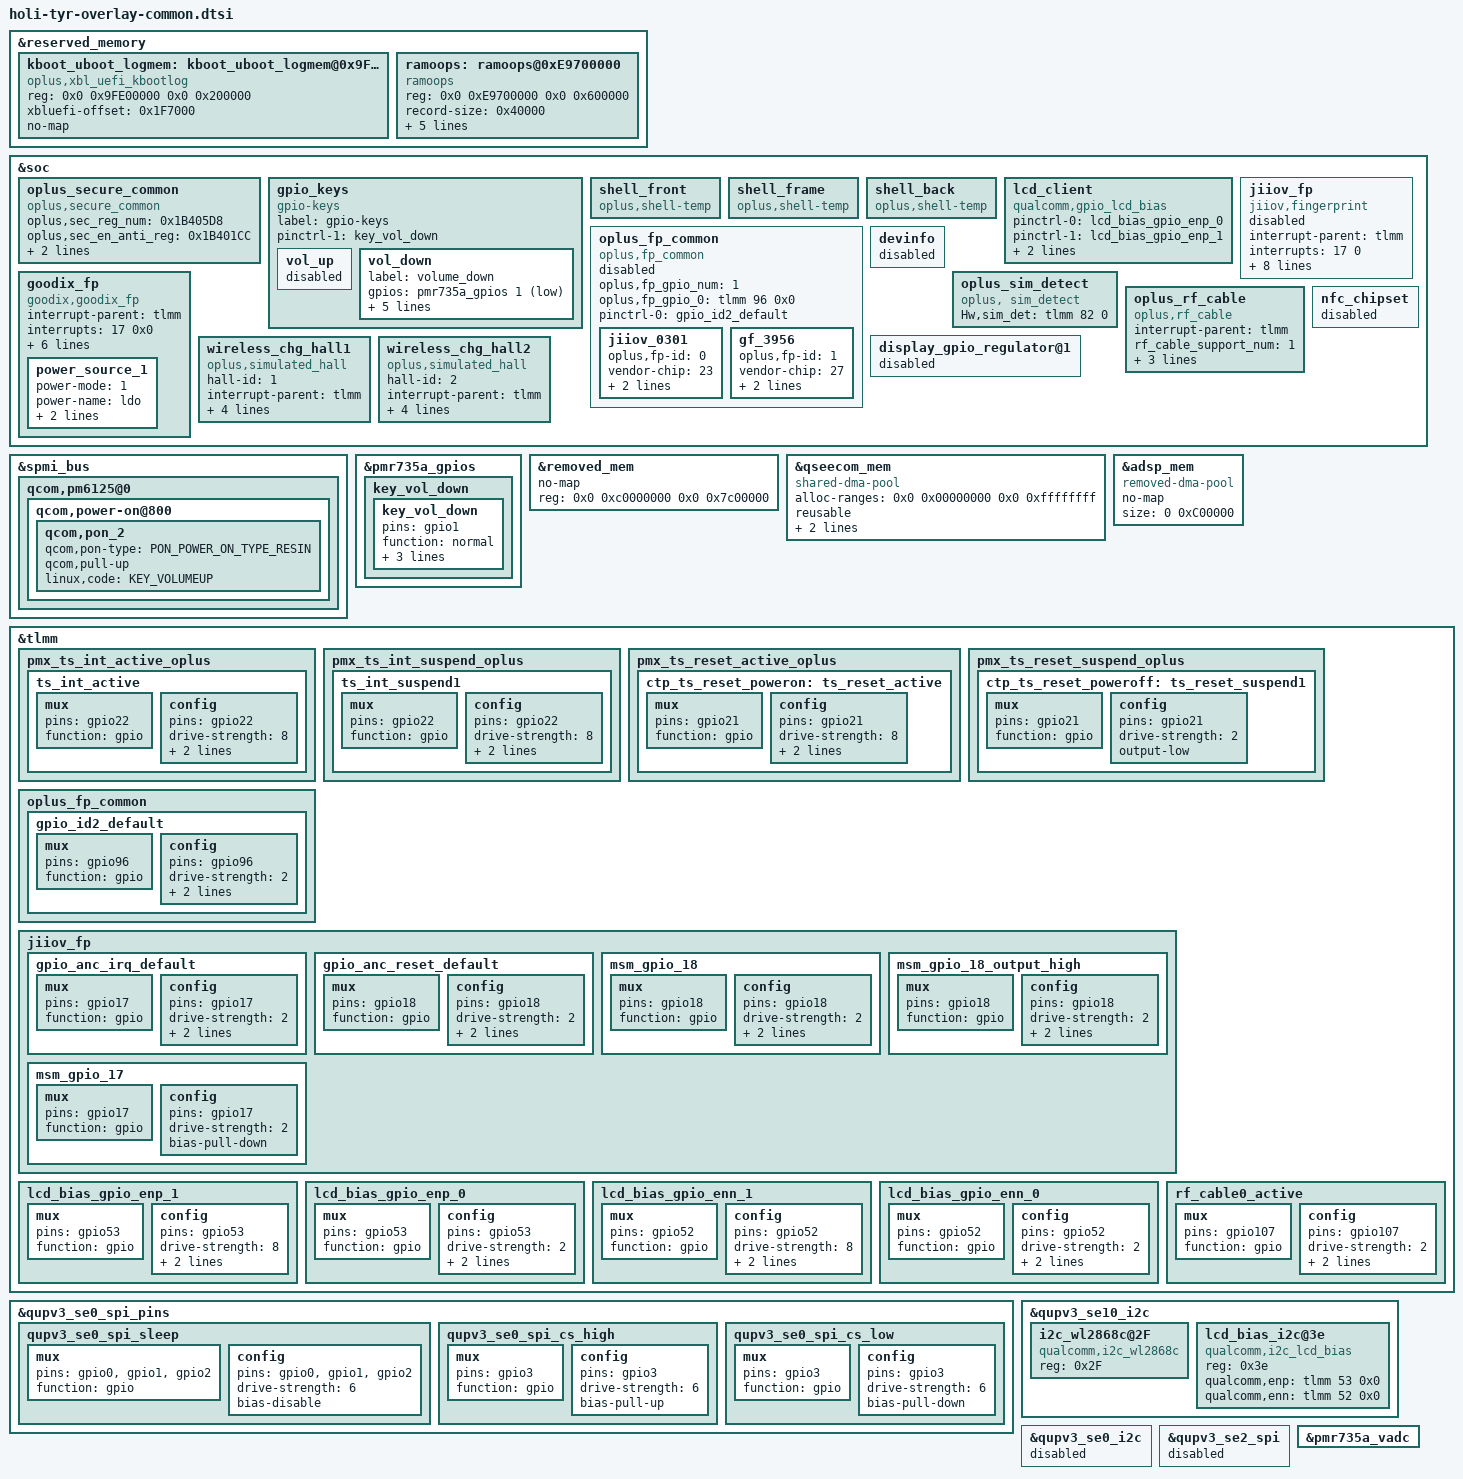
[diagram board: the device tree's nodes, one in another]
#include "../qcom/blair-qrd-nopmi.dtsi"

/* #ifdef OPLUS_ARCH_EXTENDS */
#include "holi-tyr-audio-overlay.dtsi"
/* #endif OPLUS_ARCH_EXTENDS */
/* DTBO: Platform common generic overlay */

&reserved_memory {
	//xbl_uefi_mem address get from: PcdEmbeddedFdBaseAddress +
	//SERIAL_BUFFER_OFFSET = 0x9FC00000 + 0x3F7000 = 0x9FFF7000
	//kernel boot log: 0x9FE00000~ 0x9FFF6FFF, xbl-uefi log: 0x9FFF7000 ~ 0x9FFFFFFF
	kboot_uboot_logmem: kboot_uboot_logmem@0x9FE00000 {
		reg = <0x0 0x9FE00000 0x0 0x200000>;
		compatible = "oplus,xbl_uefi_kbootlog";
		xbluefi-offset = <0x1F7000>;
		no-map;
	};

	//#if IS_ENABLED(CONFIG_OPLUS_FEATURE_DUMP_DEVICE_INFO)
	ramoops: ramoops@0xE9700000 {
		compatible = "ramoops";
		reg = <0x0 0xE9700000 0x0 0x600000>;  //6M
		record-size  = <0x40000>; //256k
		console-size = <0x40000>; //256k
		ftrace-size  = <0x100000>; //1M
		pmsg-size    = <0x100000>; //1M
		devinfo-size = <0x8000>;  //32k
		ecc-size     = <0x0>;
	 };
};

&soc{
	oplus_secure_common {
		compatible = "oplus,secure_common";
		oplus,sec_reg_num = <0x1B405D8>;
		oplus,sec_en_anti_reg = <0x1B401CC>;
		oplus,sec_override1_reg = <0x7860C0>;
		oplus,override1_en_value = <0x1>;
	};
};

&soc {
/*#ifdef OPLUS_FEATURE_TP_BASIC*/
	gpio_keys {
		compatible = "gpio-keys";
		label = "gpio-keys";

		pinctrl-names = "default";
		pinctrl-1 = <&key_vol_down>;
		/* using volume down config update the default value */

		vol_up {
                status="disabled";
		};

		vol_down {
			label = "volume_down";
			gpios = <&pmr735a_gpios 1 GPIO_ACTIVE_LOW>;
			linux,input-type = <1>;
			linux,code = <KEY_VOLUMEDOWN>;
			gpio-key,wakeup;
			debounce-interval = <15>;
			linux,can-disable;
		};
	};

	shell_front {
		compatible = "oplus,shell-temp";
	};

	shell_frame {
		compatible = "oplus,shell-temp";
	};

	shell_back {
		compatible = "oplus,shell-temp";
	};

	//#ifdef OPLUS_BUG_STABILITY
	lcd_client {
		compatible = "qualcomm,gpio_lcd_bias";
		pinctrl-names = "lcd_bias_gpio_enp0","lcd_bias_gpio_enp1","lcd_bias_gpio_enn0","lcd_bias_gpio_enn1";
		pinctrl-0 = <&lcd_bias_gpio_enp_0>;
		pinctrl-1 = <&lcd_bias_gpio_enp_1>;
		pinctrl-2 = <&lcd_bias_gpio_enn_0>;
		pinctrl-3 = <&lcd_bias_gpio_enn_1>;
		status = "okay";
	};
	//#endif
};

&spmi_bus {
	qcom,pm6125@0 {
		qcom,power-on@800 {
/*#ifdef OPLUS_FEATURE_TP_BASIC*/
			qcom,pon_2 {
					qcom,pon-type = <PON_POWER_ON_TYPE_RESIN>;
					qcom,pull-up;
					linux,code = <KEY_VOLUMEUP>;
			};
/*#endif OPLUS_FEATURE_TP_BASIC*/
		};
	};
};

&pmr735a_gpios {
	key_vol_down {
		key_vol_down: key_vol_down {
			pins = "gpio1";
			function = "normal";
			input-enable;
			bias-pull-up;
			power-source = <1>;
		};
	};
};

/* #ifdef OPLUS_FEATURE_CAMERA_COMMON */
//#include "camera/blair-camera-sensor-mtp.dtsi"
/* #endif OPLUS_FEATURE_CAMERA_COMMON */

//#ifdef OPLUS_FEATURE_FINGERPRINT
&soc{
	oplus_fp_common {
		compatible = "oplus,fp_common";
		oplus,fp_gpio_num = <1>;
		oplus,fp_gpio_0 = <&tlmm 96 0x0>;
		pinctrl-names = "default";
		pinctrl-0 = <&gpio_id2_default>;
		status = "disabled";
		jiiov_0301 {
			oplus,fp-id = <0>; /* fp id mapping table */
			vendor-chip = <23>; /* please refer to the struct fp_vendor_t in oplus_fp_commmon.h */
			eng-menu = "-1,-1"; /* represents SNR, inclination test item in engineer menu, and 0/1 means off/on */
			chip-name = "JIIOV_0301";  /* /proc/fp_id, will be displayed in engineer menu  */
		};
	gf_3956 {
            oplus,fp-id = <1>; /* fp id mapping table */
            vendor-chip = <27>; /* please refer to the struct fp_vendor_t in oplus_fp_commmon.n */
            eng-menu = "-1,-1"; /* represents SNR, inclination test item in engineer menu, and 0/1 means off/on */
            chip-name = "G_3956";  /* /proc/fp_id, will be displayed in engineer menu  */
    	};

	};

	jiiov_fp {
		status = "disabled";
		compatible = "jiiov,fingerprint";
		interrupt-parent = <&tlmm>;
		interrupts = <17 0>;
		ldo-supply = <&pm6125_l21>;
		anc,gpio_irq = <&tlmm 17 0x1>;
		anc,gpio_rst = <&tlmm 18 0x0>;
		pinctrl-names = "default", "anc_reset_reset", "anc_reset_active", "anc_irq_active";
		pinctrl-0 = <&gpio_anc_irq_default>, <&gpio_anc_reset_default>;
		pinctrl-1 = <&msm_gpio_18>;
		pinctrl-2 = <&msm_gpio_18_output_high>;
		pinctrl-3 = <&msm_gpio_17>;
	};

	goodix_fp {
		status = "okay";
		compatible = "goodix,goodix_fp";
		interrupt-parent = <&tlmm>;
		interrupts = <17 0x0>;
		//ldo-supply = <&L21A>;
		//power-mode = <1>;
		ldo-supply = <&pm6125_l21>;
		goodix,gpio_irq = <&tlmm 17 0x00>;
		goodix,gpio_reset = <&tlmm 18 0x00>;
		//gpio-power = <&tlmm 47 0x0>;
		notify_tpinfo_flag = <1>;
		ftm_poweroff_flag = <1>;
		ldo-config = <3300000 3300000 150000>;
		power_source_1 {
			power-mode = <1>;
			power-name = "ldo";
			power-config = "ldo-config";
			delay-time = <0>;
		};
		
	};
};
&removed_mem {
	no-map;
	//reg = <0x0 0xc0000000 0x0 0x5100000>;
	reg = <0x0 0xc0000000 0x0 0x7c00000>;
};

&qseecom_mem {
	compatible = "shared-dma-pool";
	alloc-ranges = <0x0 0x00000000 0x0 0xffffffff>;
	reusable;
	alignment = <0x0 0x400000>;
	//size = <0x0 0x1400000>;
	size = <0x0 0x5c00000>;
};
//#endif /*OPLUS_FEATURE_FINGERPRINT*

&adsp_mem {
    compatible = "removed-dma-pool";
    no-map;
    /delete-property/ reusable;
    size = <0 0xC00000>;
};

//#ifdef OPLUS_FEATURE_TP_BASIC
&soc {
	devinfo {
		status = "disabled";
	};

    //#ifdef OPLUS_FEATURE_TP_BASIC
	oplus_sim_detect {
		compatible = "oplus, sim_detect";
		Hw,sim_det = <&tlmm 82 0>;
	};
    //#endif /* OPLUS_FEATURE_TP_BASIC */
};

&tlmm {
	/* add pingrp for touchscreen */
	pmx_ts_int_active_oplus {
		ts_int_active: ts_int_active {
			mux {
				pins = "gpio22";
				function = "gpio";
			};

			config {
				pins = "gpio22";
				drive-strength = <8>;
				bias-disable;
				input-enable;
			};
		};
	};

	pmx_ts_int_suspend_oplus {
		ts_int_suspend1: ts_int_suspend1 {
			mux {
				pins = "gpio22";
				function = "gpio";
			};

			config {
				pins = "gpio22";
				drive-strength = <8>;
				//bias-pull-down;
				bias-pull-up;
				input-enable;
			};
		};
	};

	pmx_ts_reset_active_oplus {
		ctp_ts_reset_poweron: ts_reset_active {
			mux {
				pins = "gpio21";
				function = "gpio";
			};

			config {
				pins = "gpio21";
				drive-strength = <8>;
				output-high;
				bias-disable;
			};
		};
	};

	pmx_ts_reset_suspend_oplus {
		ctp_ts_reset_poweroff: ts_reset_suspend1 {
			mux {
				pins = "gpio21";
				function = "gpio";
			};

			config {
				pins = "gpio21";
				drive-strength = <2>;
				output-low;
			};
		};
	};

	//#ifdef OPLUS_FEATURE_FINGERPRINT
	oplus_fp_common{
		gpio_id2_default: gpio_id2_default {
			mux {
				pins = "gpio96";
				function = "gpio";
			};
			config {
				pins = "gpio96";
				drive-strength = <2>;
				bias-pull-up;
				input-enable;
			};
		};
	};

	jiiov_fp{
		gpio_anc_irq_default: gpio_anc_irq_default {
			mux {
				pins = "gpio17";
				function = "gpio";
			};
			config {
				pins = "gpio17";
				drive-strength = <2>;
				bias-pull-down;
				input-enable;
			};
		};
		gpio_anc_reset_default: gpio_anc_reset_default {
			mux {
				pins = "gpio18";
				function = "gpio";
			};
			config {
				pins = "gpio18";
				drive-strength = <2>;
				bias-disable;
				output-low;
			};
		};

		msm_gpio_18: msm_gpio_18 {
			mux {
				pins = "gpio18";
				function = "gpio";
			};

			config {
				pins = "gpio18";
				drive-strength = <2>;
				bias-disable;
				output-low;
			};
		};

		msm_gpio_18_output_high: msm_gpio_18_output_high {
			mux {
				pins = "gpio18";
				function = "gpio";
			};

			config {
				pins = "gpio18";
				drive-strength = <2>;
				bias-disable;
				output-high;
			};
		};

		msm_gpio_17: msm_gpio_17 {
			mux {
				pins = "gpio17";
				function = "gpio";
			};

			config {
				pins = "gpio17";
				drive-strength = <2>;
				bias-pull-down;
			};
		};
	};
	//#endif /*OPLUS_FEATURE_FINGERPRINT*


	//#ifdef OPLUS_BUG_STABILITY
	lcd_bias_gpio_enp_1: lcd_bias_gpio_enp_1 {
		mux {
			pins = "gpio53";
			function = "gpio";
		};

		config {
			pins = "gpio53";
			drive-strength = <8>;
			output-high;
			bias-pull-up;
		};
	};

	lcd_bias_gpio_enp_0: lcd_bias_gpio_enp_0 {
		mux {
			pins = "gpio53";
			function = "gpio";
		};

		config {
			pins = "gpio53";
			drive-strength = <2>;
			output-low;
			bias-pull-down;
		};
	};

	lcd_bias_gpio_enn_1: lcd_bias_gpio_enn_1 {
		mux {
			pins = "gpio52";
			function = "gpio";
		};

		config {
			pins = "gpio52";
			drive-strength = <8>;
			output-high;
			bias-pull-up;
		};
	};

	lcd_bias_gpio_enn_0: lcd_bias_gpio_enn_0 {
		mux {
			pins = "gpio52";
			function = "gpio";
		};

		config {
			pins = "gpio52";
			drive-strength = <2>;
			output-low;
			bias-pull-down;
		};
	};
	//#endif
};

&qupv3_se0_spi_pins {
	qupv3_se0_spi_sleep: qupv3_se0_spi_sleep {
		mux {
			pins = "gpio0", "gpio1",
					"gpio2";
			function = "gpio";
		};

		config {
			pins = "gpio0", "gpio1",
					"gpio2";
			drive-strength = <6>;
			bias-disable;
		};
	};

	qupv3_se0_spi_cs_high: qupv3_se0_spi_cs_high {
		mux {
			pins = "gpio3";
			function = "gpio";
		};

		config {
			pins = "gpio3";
			drive-strength = <6>;
			bias-pull-up;
		};
	};

	qupv3_se0_spi_cs_low: qupv3_se0_spi_cs_low {
		mux {
			pins = "gpio3";
			function = "gpio";
		};

		config {
			pins = "gpio3";
			drive-strength = <6>;
			bias-pull-down;
		};
	};
};

&qupv3_se10_i2c {
	#address-cells = <1>;
	#size-cells = <0>;

	status = "okay";

	i2c_wl2868c@2F{
		compatible = "qualcomm,i2c_wl2868c";
		reg = <0x2F>;
		status = "okay";
	};

	//#ifdef OPLUS_BUG_STABILITY
	lcd_bias_i2c@3e {
		compatible = "qualcomm,i2c_lcd_bias";
		reg = <0x3e>;
		qualcomm,enp = <&tlmm 53 0x0>;
		qualcomm,enn = <&tlmm 52 0x0>;
		status = "okay";
	};
	//#endif
};

//#ifdef OPLUS_FEATURE_RF_CALBLE
&tlmm {
	rf_cable0_active: rf_cable0_active {
		mux {
			pins = "gpio107";
			function = "gpio";
		};
		config {
			pins = "gpio107";
			drive-strength = <2>;
			input-enable;
			bias-pull-up;
		};
	};
};

&soc {
	oplus_rf_cable {
		compatible = "oplus,rf_cable";
		interrupt-parent = <&tlmm>;
		rf_cable_support_num = <1>;
		rf,cable0-gpio = <&tlmm 107 0>;
		//rf,cable1-gpio = <&tlmm 51 0>;
		rf,cable-support-timer = <0>;
		pinctrl-names = "rf_cable_active";
		pinctrl-0 = <&rf_cable0_active>;
	};
};
//#endif /*OPLUS_FEATURE_RF_CALBLE*/

//Begin:Added by xiewei@vanyol.com BSP.TP for disable NFC as io conflict
&soc {
	nfc_chipset {
        status = "disabled";
	};

	display_gpio_regulator@1 {
		status = "disabled";
	};
};

&qupv3_se0_i2c {
	status = "disabled";
};

#include "tyr-touchpanel.dtsi"
//End:added by xiewei@vanyol.com

&qupv3_se2_spi {
       status = "disabled";
};

//wulihong@vanyol.com added for reset gpio mux situation.
&pmr735a_vadc {
	/delete-property/ pinctrl-names;
	/delete-property/ pinctrl-0;
};

//Begin:Added by liujian@vanyol.com BSP.Sensor for hall sensor
&soc {
    wireless_chg_hall1 {
        compatible = "oplus,simulated_hall";
        hall-id = <1>;

        interrupt-parent = <&tlmm>;
        interrupts = <97 0x2003>;      //both rising and falling edge
        irq-gpio = <&tlmm 97 0x2003>;
        optional-handle-type = <1>;
        irq_active_low;
    };

    wireless_chg_hall2 {
        compatible = "oplus,simulated_hall";
        hall-id = <2>;

        interrupt-parent = <&tlmm>;
        interrupts = <134 0x2003>;      //both rising and falling edge
        irq-gpio = <&tlmm 134 0x2003>;
        optional-handle-type = <1>;
        irq_active_low;
    };
};
//End:added by liujian@vanyol.com

/*disable modem when temp above 55C,add by qujiong@vanyol.com*/
/* &thermal_zones {
	quiet-therm2-step {
		polling-delay-passive = <2000>;
		polling-delay = <0>;
		thermal-governor = "step_wise";
		thermal-sensors = <&pm6125_adc_tm ADC5_AMUX_THM2_100K_PU>;
		wake-capable-sensor;
		trips {
			modem_trip0: modem-trip0 {
				temperature = <58000>;
				hysteresis = <2000>;
				type = "passive";
                        };

			modem_trip1: modem-trip1 {
                                temperature = <58000>;
                                hysteresis = <2000>;
                                type = "passive";
                        };
                };
		cooling-maps {
                        modem_cdev0 {
                                trip = <&modem_trip0>;
                                cooling-device = <&modem_tj 3 3>;
                        };

                        modem_cdev1 {
                                trip = <&modem_trip1>;
                                cooling-device = <&modem_pa 3 3>;
                        };

                };
        };
}; */
